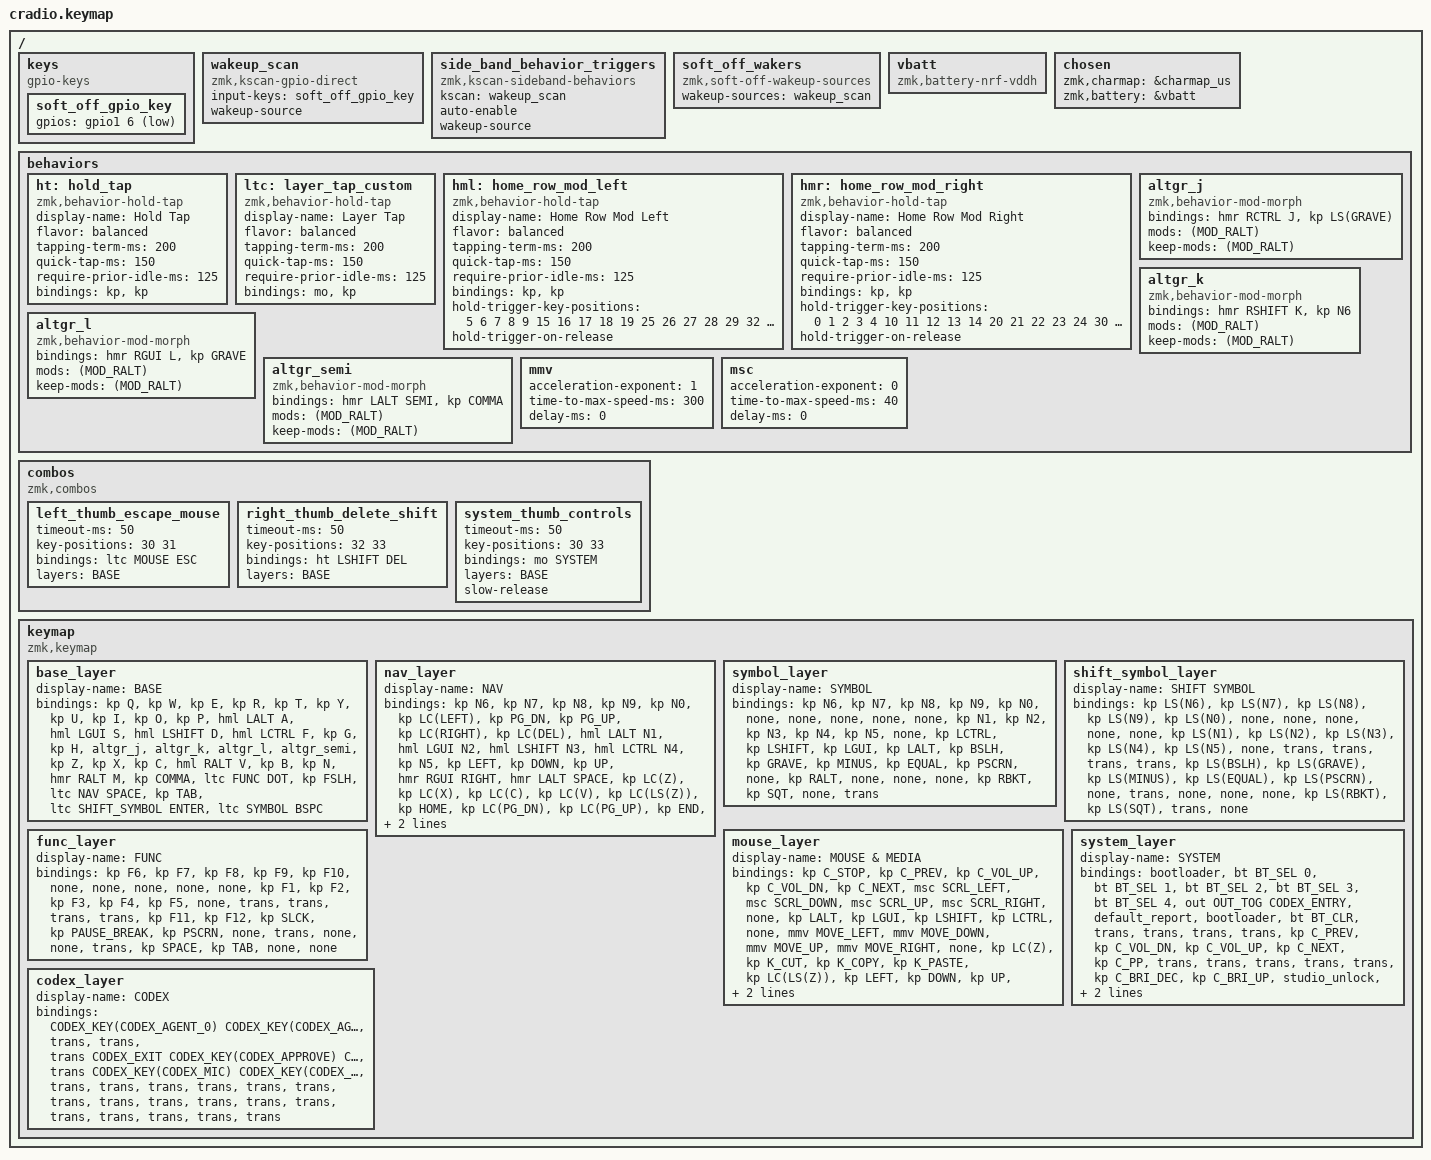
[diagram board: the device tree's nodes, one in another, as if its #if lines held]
// Copyright (c) 2022 The ZMK Contributors
// SPDX-License-Identifier: MIT

#define ZMK_POINTING_DEFAULT_MOVE_VAL 2500  // 600
#define ZMK_POINTING_DEFAULT_SCRL_VAL 20    // 10

#include <behaviors.dtsi>
#include "behaviors/character_map.dtsi"
#include "behaviors/send_string.dtsi"
#include "behaviors/report.dtsi"
#include <dt-bindings/zmk/bt.h>
#include <dt-bindings/zmk/keys.h>
#include <dt-bindings/zmk/outputs.h>
#include <dt-bindings/zmk/pointing.h>
#if defined(NXTKB_CODEX_MICRO)
#include <dt-bindings/nxtkb/codex.h>
#include <behaviors/codex_key.dtsi>
#endif

#define BASE 0
#define NAV 1
#define SYMBOL 2
#define SHIFT_SYMBOL 3
#define FUNC 4
#define MOUSE 5
#define SYSTEM 6
#define CODEX 7

#if defined(NXTKB_CODEX_MICRO)
#define CODEX_ENTRY &tog CODEX
#define CODEX_EXIT &tog CODEX
#define CODEX_KEY(n) &codex_key n
#else
#define CODEX_ENTRY &trans
#define CODEX_EXIT &trans
#define CODEX_KEY(n) &trans
#endif

// https://zmk.dev/docs/development/hardware-integration/soft-off-setup?advanced-methods=wakeup&kscan-type=dkscan
/ {
    keys {
        compatible = "gpio-keys";
        soft_off_gpio_key: soft_off_gpio_key {
            gpios = <&gpio1 6 (GPIO_ACTIVE_LOW | GPIO_PULL_UP)>;
        };
    };
    wakeup_scan: wakeup_scan {
        compatible = "zmk,kscan-gpio-direct";
        input-keys = <&soft_off_gpio_key>;
        wakeup-source;
    };
    side_band_behavior_triggers: side_band_behavior_triggers {
        compatible = "zmk,kscan-sideband-behaviors";
        kscan = <&wakeup_scan>;
        auto-enable;
        wakeup-source;
    };
    soft_off_wakers {
        compatible = "zmk,soft-off-wakeup-sources";
        wakeup-sources = <&wakeup_scan>;
    };
};

/ {
    vbatt: vbatt {
        compatible = "zmk,battery-nrf-vddh";
    };
    chosen {
        zmk,charmap = &charmap_us;
        zmk,battery = &vbatt;
    };

    behaviors {
        // Generic mod-tap used by the right-thumb combo.
        ht: hold_tap {
            display-name = "Hold Tap";
            compatible = "zmk,behavior-hold-tap";
            #binding-cells = <2>;
            flavor = "balanced";
            tapping-term-ms = <200>;
            quick-tap-ms = <150>;
            require-prior-idle-ms = <125>;
            bindings = <&kp>, <&kp>;
        };

        // Layer-tap equivalent for the four thumb keys and Dot/FUNC.
        ltc: layer_tap_custom {
            display-name = "Layer Tap";
            compatible = "zmk,behavior-hold-tap";
            #binding-cells = <2>;
            flavor = "balanced";
            tapping-term-ms = <200>;
            quick-tap-ms = <150>;
            require-prior-idle-ms = <125>;
            bindings = <&mo>, <&kp>;
        };

        // Positional hold-taps reproduce QMK Chordal Hold: a home-row
        // modifier becomes a hold only when the other hand joins the chord.
        hml: home_row_mod_left {
            display-name = "Home Row Mod Left";
            compatible = "zmk,behavior-hold-tap";
            #binding-cells = <2>;
            flavor = "balanced";
            tapping-term-ms = <200>;
            quick-tap-ms = <150>;
            require-prior-idle-ms = <125>;
            bindings = <&kp>, <&kp>;
            hold-trigger-key-positions = <5 6 7 8 9 15 16 17 18 19 25 26 27 28 29 32 33>;
            hold-trigger-on-release;
        };

        hmr: home_row_mod_right {
            display-name = "Home Row Mod Right";
            compatible = "zmk,behavior-hold-tap";
            #binding-cells = <2>;
            flavor = "balanced";
            tapping-term-ms = <200>;
            quick-tap-ms = <150>;
            require-prior-idle-ms = <125>;
            bindings = <&kp>, <&kp>;
            hold-trigger-key-positions = <0 1 2 3 4 10 11 12 13 14 20 21 22 23 24 30 31>;
            hold-trigger-on-release;
        };

        // Preserve the four Vial AltGr key overrides without giving up the
        // home-row modifiers on J, K, L, and semicolon. keep-mods leaves
        // Right Alt pressed while the replacement keycode is emitted.
        altgr_j: altgr_j {
            compatible = "zmk,behavior-mod-morph";
            #binding-cells = <0>;
            bindings = <&hmr RCTRL J>, <&kp LS(GRAVE)>;
            mods = <(MOD_RALT)>;
            keep-mods = <(MOD_RALT)>;
        };

        altgr_k: altgr_k {
            compatible = "zmk,behavior-mod-morph";
            #binding-cells = <0>;
            bindings = <&hmr RSHIFT K>, <&kp N6>;
            mods = <(MOD_RALT)>;
            keep-mods = <(MOD_RALT)>;
        };

        altgr_l: altgr_l {
            compatible = "zmk,behavior-mod-morph";
            #binding-cells = <0>;
            bindings = <&hmr RGUI L>, <&kp GRAVE>;
            mods = <(MOD_RALT)>;
            keep-mods = <(MOD_RALT)>;
        };

        altgr_semi: altgr_semi {
            compatible = "zmk,behavior-mod-morph";
            #binding-cells = <0>;
            bindings = <&hmr LALT SEMI>, <&kp COMMA>;
            mods = <(MOD_RALT)>;
            keep-mods = <(MOD_RALT)>;
        };

        mmv {
            acceleration-exponent = <1>;     // 1
            time-to-max-speed-ms = <300>;    // 40
            delay-ms = <0>;                  // 0
        };
        msc {
            acceleration-exponent = <0>;     // 0
            time-to-max-speed-ms = <40>;     // 500
            delay-ms = <0>;                  // 10
        };
    };

    // Vial combos 3 and 4. Restricting them to BASE matches their original
    // keycode-based behavior and prevents surprises on the other layers.
    combos {
        compatible = "zmk,combos";

        left_thumb_escape_mouse {
            timeout-ms = <50>;
            key-positions = <30 31>;
            bindings = <&ltc MOUSE ESC>;
            layers = <BASE>;
        };

        right_thumb_delete_shift {
            timeout-ms = <50>;
            key-positions = <32 33>;
            bindings = <&ht LSHIFT DEL>;
            layers = <BASE>;
        };

        // Cross-hand outer-thumb chord for firmware and connection controls.
        system_thumb_controls {
            timeout-ms = <50>;
            key-positions = <30 33>;
            bindings = <&mo SYSTEM>;
            layers = <BASE>;
            slow-release;
        };
    };

    keymap {
        compatible = "zmk,keymap";

        base_layer {
            display-name = "BASE";
            bindings = <
            &kp Q           &kp W           &kp E            &kp R           &kp T        &kp Y        &kp U           &kp I            &kp O           &kp P
            &hml LALT A     &hml LGUI S     &hml LSHIFT D     &hml LCTRL F    &kp G        &kp H        &altgr_j       &altgr_k         &altgr_l        &altgr_semi
            &kp Z           &kp X           &kp C            &hml RALT V     &kp B        &kp N        &hmr RALT M     &kp COMMA        &ltc FUNC DOT    &kp FSLH
            &ltc NAV SPACE  &kp TAB         &ltc SHIFT_SYMBOL ENTER          &ltc SYMBOL BSPC
            >;
        };

        nav_layer {
            display-name = "NAV";
            bindings = <
            &kp N6          &kp N7          &kp N8           &kp N9          &kp N0       &kp LC(LEFT)  &kp PG_DN       &kp PG_UP        &kp LC(RIGHT)   &kp LC(DEL)
            &hml LALT N1    &hml LGUI N2    &hml LSHIFT N3   &hml LCTRL N4   &kp N5       &kp LEFT      &kp DOWN        &kp UP           &hmr RGUI RIGHT &hmr LALT SPACE
            &kp LC(Z)       &kp LC(X)       &kp LC(C)        &kp LC(V)       &kp LC(LS(Z)) &kp HOME     &kp LC(PG_DN)  &kp LC(PG_UP)   &kp END         &kp LC(BSPC)
            &trans          &kp TAB         &hmr LC(LSHIFT) ENTER           &hmr LCTRL BSPC
            >;
        };

        symbol_layer {
            display-name = "SYMBOL";
            bindings = <
            &kp N6          &kp N7          &kp N8           &kp N9          &kp N0       &none         &none            &none             &none            &none
            &kp N1          &kp N2          &kp N3           &kp N4          &kp N5       &none         &kp LCTRL        &kp LSHIFT        &kp LGUI         &kp LALT
            &kp BSLH        &kp GRAVE       &kp MINUS        &kp EQUAL       &kp PSCRN    &none         &kp RALT         &none             &none            &none
            &kp RBKT        &kp SQT         &none            &trans
            >;
        };

        shift_symbol_layer {
            display-name = "SHIFT SYMBOL";
            bindings = <
            &kp LS(N6)      &kp LS(N7)      &kp LS(N8)       &kp LS(N9)      &kp LS(N0)   &none         &none            &none             &none            &none
            &kp LS(N1)      &kp LS(N2)      &kp LS(N3)       &kp LS(N4)      &kp LS(N5)   &none         &trans           &trans            &trans           &trans
            &kp LS(BSLH)    &kp LS(GRAVE)   &kp LS(MINUS)    &kp LS(EQUAL)   &kp LS(PSCRN) &none        &trans           &none             &none            &none
            &kp LS(RBKT)    &kp LS(SQT)     &trans           &none
            >;
        };

        func_layer {
            display-name = "FUNC";
            bindings = <
            &kp F6          &kp F7          &kp F8           &kp F9          &kp F10      &none         &none            &none             &none            &none
            &kp F1          &kp F2          &kp F3           &kp F4          &kp F5       &none         &trans           &trans            &trans           &trans
            &kp F11         &kp F12         &kp SLCK         &kp PAUSE_BREAK &kp PSCRN    &none         &trans           &none             &none            &trans
            &kp SPACE       &kp TAB         &none            &none
            >;
        };

        mouse_layer {
            display-name = "MOUSE & MEDIA";
            bindings = <
            &kp C_STOP      &kp C_PREV      &kp C_VOL_UP     &kp C_VOL_DN    &kp C_NEXT   &msc SCRL_LEFT &msc SCRL_DOWN &msc SCRL_UP      &msc SCRL_RIGHT &none
            &kp LALT        &kp LGUI        &kp LSHIFT       &kp LCTRL       &none        &mmv MOVE_LEFT &mmv MOVE_DOWN &mmv MOVE_UP      &mmv MOVE_RIGHT &none
            &kp LC(Z)       &kp K_CUT       &kp K_COPY       &kp K_PASTE     &kp LC(LS(Z)) &kp LEFT     &kp DOWN        &kp UP            &kp RIGHT       &kp LC(Z)
            &kp C_MUTE      &kp C_PP        &mkp LCLK        &mkp MCLK
            >;
        };

        system_layer {
            display-name = "SYSTEM";
            bindings = <
            &bootloader     &bt BT_SEL 0    &bt BT_SEL 1     &bt BT_SEL 2    &bt BT_SEL 3 &bt BT_SEL 4 &out OUT_TOG    CODEX_ENTRY      &default_report &bootloader
            &bt BT_CLR      &trans          &trans           &trans          &trans       &kp C_PREV   &kp C_VOL_DN    &kp C_VOL_UP      &kp C_NEXT      &kp C_PP
            &trans          &trans          &trans           &trans          &trans       &kp C_BRI_DEC &kp C_BRI_UP   &studio_unlock    &soft_off       &kp C_MUTE
            &trans          &trans          &trans           &trans
            >;
        };

#if defined(NXTKB_CODEX_MICRO)
        codex_layer {
            display-name = "CODEX";
            bindings = <
            CODEX_KEY(CODEX_AGENT_0)  CODEX_KEY(CODEX_AGENT_1)  CODEX_KEY(CODEX_AGENT_2)  CODEX_KEY(CODEX_AGENT_3)  CODEX_KEY(CODEX_AGENT_4)  CODEX_KEY(CODEX_AGENT_5)  &trans  &trans  &trans  CODEX_EXIT
            CODEX_KEY(CODEX_APPROVE)  CODEX_KEY(CODEX_SPLIT)    CODEX_KEY(CODEX_DECLINE)  CODEX_KEY(CODEX_FAST)     &trans                    CODEX_KEY(CODEX_MIC)      CODEX_KEY(CODEX_SEND)  &trans  &trans  &trans
            &trans                    &trans                    &trans                      &trans                      &trans                    &trans                    &trans                 &trans  &trans  &trans
            &trans                    &trans                    &trans                      &trans
            >;
        };
#endif
    };
};
